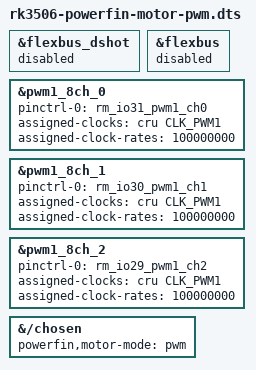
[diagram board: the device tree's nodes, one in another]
// SPDX-License-Identifier: (GPL-2.0+ OR MIT)
/*
 * PowerFin feature overlay: route FlexBUS0 D0-D2 to PWM1 channels 0-2.
 * FlexBUS0 D3 is deliberately left unused.
 */

/dts-v1/;
/plugin/;

#include <dt-bindings/clock/rockchip,rk3506-cru.h>

&flexbus_dshot {
	status = "disabled";
};

&flexbus {
	status = "disabled";
};

&pwm1_8ch_0 {
	status = "okay";
	pinctrl-names = "active";
	pinctrl-0 = <&rm_io31_pwm1_ch0>;
	assigned-clocks = <&cru CLK_PWM1>;
	assigned-clock-rates = <100000000>;
};

&pwm1_8ch_1 {
	status = "okay";
	pinctrl-names = "active";
	pinctrl-0 = <&rm_io30_pwm1_ch1>;
	assigned-clocks = <&cru CLK_PWM1>;
	assigned-clock-rates = <100000000>;
};

&pwm1_8ch_2 {
	status = "okay";
	pinctrl-names = "active";
	pinctrl-0 = <&rm_io29_pwm1_ch2>;
	assigned-clocks = <&cru CLK_PWM1>;
	assigned-clock-rates = <100000000>;
};

&{/chosen} {
	powerfin,motor-mode = "pwm";
};
